# SKEAZ1284 register map
File version: 1.6
Registers are 8-bit, read-write, reset 0x0 unless marked. A register's access mark holds for its fields unless they carry their own. Offsets are from the block's base; [hi:lo] are bit positions; {n}, {i} and the like mark numbered series.

## ADC — Analog-to-digital converter
Base 0x4003B000; register names take the prefix ADC_
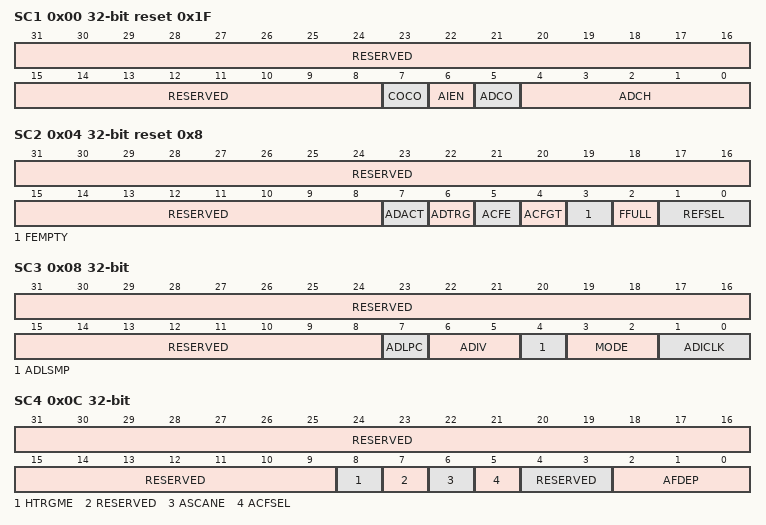
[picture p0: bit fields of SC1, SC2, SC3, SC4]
0x00 SC1 32-bit reset 0x1F — Status and Control Register 1
  [31:8] RESERVED ro
  [7] COCO ro — Conversion Complete Flag
    0=Conversion not completed; 1=Conversion completed
  [6] AIEN — Interrupt Enable
    0=Conversion complete interrupt disabled; 1=Conversion complete interrupt enabled
  [5] ADCO — Continuous Conversion Enable
    0=One conversion following a write to the ADC_SC1 when software triggered operation is selected, or one conversion following assertion of ADHWT when hardware triggered operation is selected. When the FIFO function is enabled (AFDEP > 0), a set of conversion are triggered when ADC_SC2[ADTRG]=0 or both ADC_SC2[ADTRG]=1 and ADC_SC4[HTRGME]=1.; 1=Continuous conversions are initiated following a write to ADC_SC1 when software triggered operation is selected. Continuous conversions are initiated by an ADHWT event when hardware triggered operation is selected. When the FIFO function is enabled (AFDEP > 0), a set of conversions are loop triggered.
  [4:0] ADCH — Input Channel Select
    22=Temperature Sensor; 23=Bandgap; 29=VREFH; 30=VREFL; 31=Module disabled Reset FIFO in FIFO mode
0x04 SC2 32-bit reset 0x8 — Status and Control Register 2
  [31:8] RESERVED ro
  [7] ADACT ro — Conversion Active
    0=Conversion not in progress; 1=Conversion in progress
  [6] ADTRG — Conversion Trigger Select
    0=Software trigger selected; 1=Hardware trigger selected
  [5] ACFE — Compare Function Enable
    0=Compare function disabled; 1=Compare function enabled
  [4] ACFGT — Compare Function Greater Than Enable
    0=Compare triggers when input is less than compare level; 1=Compare triggers when input is greater than or equal to compare level
  [3] FEMPTY ro — Result FIFO empty
    0=Indicates that ADC result FIFO have at least one valid new data; 1=Indicates that ADC result FIFO have no valid new data
  [2] FFULL ro — Result FIFO full
    0=Indicates that ADC result FIFO is not full and next conversion data still can be stored into FIFO; 1=Indicates that ADC result FIFO is full and next conversion will override old data in case of no read action
  [1:0] REFSEL — Voltage Reference Selection
    0=Default voltage reference pin pair (VREFH/VREFL); 1=Analog supply pin pair (VDDA/VSSA); 3=Reserved - Selects default voltage reference (VREFH/VREFL) pin pair
0x08 SC3 32-bit — Status and Control Register 3
  [31:8] RESERVED ro
  [7] ADLPC — Low-Power Configuration
    0=High speed configuration; 1=Low power configuration:The power is reduced at the expense of maximum clock speed
  [6:5] ADIV — Clock Divide Select
    0=Divide ration = 1, and clock rate = Input clock; 1=Divide ration = 2, and clock rate = Input clock * 2; 2=Divide ration = 3, and clock rate = Input clock * 4; 3=Divide ration = 4, and clock rate = Input clock * 8
  [4] ADLSMP — Long Sample Time Configuration
    0=Short sample time; 1=Long sample time
  [3:2] MODE — Conversion Mode Selection
    0=8-bit conversion (N = 8); 1=10-bit conversion (N = 10); 2=12-bit conversion (N = 12)
  [1:0] ADICLK — Input Clock Select
    0=Bus clock; 1=Bus clock divided by 2; 2=Alternate clock (ALTCLK); 3=Asynchronous clock (ADACK)
0x0C SC4 32-bit — Status and Control Register 4
  [31:9] RESERVED ro
  [8] HTRGME — Hardware Trigger Multiple Conversion Enable
    0=One hardware trigger pulse triggers one conversion; 1=One hardware trigger pulse triggers multiple conversions in fifo mode
  [7] RESERVED ro
  [6] ASCANE — FIFO Scan Mode Enable
    0=FIFO scan mode disabled; 1=FIFO scan mode enabled
  [5] ACFSEL — Compare Function Selection
    0=OR all of compare trigger; 1=AND all of compare trigger
  [4:3] RESERVED ro
  [2:0] AFDEP — FIFO Depth
    0=FIFO is disabled; {v}={v+1}-level FIFO is enabled (v=1..7)
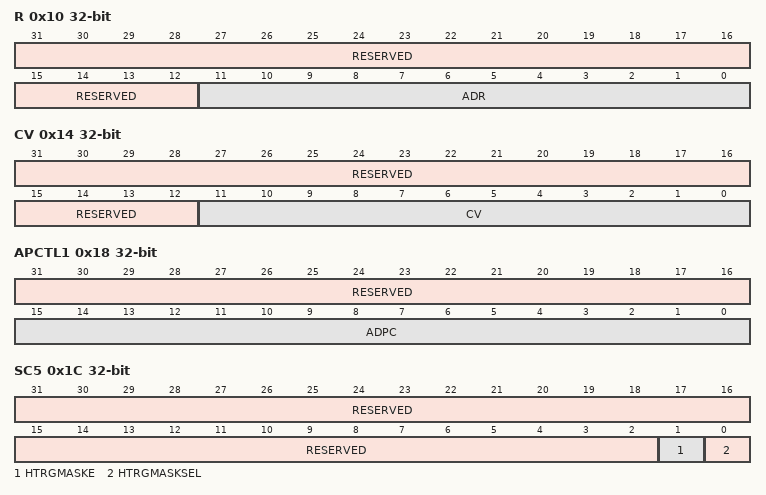
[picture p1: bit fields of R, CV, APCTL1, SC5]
0x10 R 32-bit ro — Conversion Result Register
  [31:12] RESERVED
  [11:0] ADR — Conversion Result
0x14 CV 32-bit — Compare Value Register
  [31:12] RESERVED ro
  [11:0] CV — Conversion Result[11:0]
0x18 APCTL1 32-bit — Pin Control 1 Register
  [31:16] RESERVED ro
  [15:0] ADPC — ADC Pin Control
    0=ADx pin I/O control enabled; 1=ADx pin I/O control disabled
0x1C SC5 32-bit — Status and Control Register 5
  [31:2] RESERVED ro
  [1] HTRGMASKE — Hardware Trigger Mask Enable
    0=Hardware trigger mask disable; 1=Hardware trigger mask enable and hardware trigger cannot trigger ADC conversion
  [0] HTRGMASKSEL — Hardware Trigger Mask Mode Select
    0=Hardware trigger mask with HTRGMASKE; 1=Hardware trigger mask automatically when data fifo is not empty
